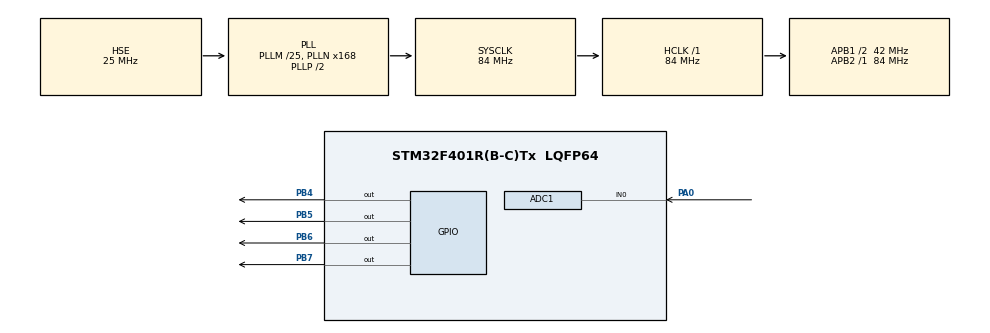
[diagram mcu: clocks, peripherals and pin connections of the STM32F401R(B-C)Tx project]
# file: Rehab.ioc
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ADC1.Channel-0\#ChannelRegularConversion=ADC_CHANNEL_0
ADC1.ContinuousConvMode=ENABLE
ADC1.DMAContinuousRequests=ENABLE
ADC1.NbrOfConversion=1
ADC1.NbrOfConversionFlag=1
ADC1.Rank-0\#ChannelRegularConversion=1
ADC1.SamplingTime-0\#ChannelRegularConversion=ADC_SAMPLETIME_84CYCLES
ADC1.master=1
Dma.ADC1.0.Direction=DMA_PERIPH_TO_MEMORY
Dma.ADC1.0.FIFOMode=DMA_FIFOMODE_DISABLE
Dma.ADC1.0.Instance=DMA2_Stream0
Dma.ADC1.0.MemDataAlignment=DMA_MDATAALIGN_WORD
Dma.ADC1.0.MemInc=DMA_MINC_ENABLE
Dma.ADC1.0.Mode=DMA_CIRCULAR
Dma.ADC1.0.PeriphDataAlignment=DMA_PDATAALIGN_WORD
Dma.ADC1.0.PeriphInc=DMA_PINC_DISABLE
Dma.ADC1.0.Priority=DMA_PRIORITY_LOW
Dma.Request0=ADC1
Mcu.Family=STM32F4
Mcu.Name=STM32F401R(B-C)Tx
Mcu.Package=LQFP64
NVIC.ADC_IRQn=true\:1\:0\:true\:false\:true\:true\:true\:true
NVIC.DMA2_Stream0_IRQn=true\:0\:0\:false\:false\:true\:false\:true\:true
NVIC.PriorityGroup=NVIC_PRIORITYGROUP_4
PA0-WKUP.Signal=ADCx_IN0
PB4.Signal=GPIO_Output
PB5.Signal=GPIO_Output
PB6.Signal=GPIO_Output
PB7.Signal=GPIO_Output
PH0\ -\ OSC_IN.Mode=HSE-External-Oscillator
PH0\ -\ OSC_IN.Signal=RCC_OSC_IN
PH1\ -\ OSC_OUT.Mode=HSE-External-Oscillator
PH1\ -\ OSC_OUT.Signal=RCC_OSC_OUT
ProjectManager.HeapSize=0x200
ProjectManager.StackSize=0x400
ProjectManager.TargetToolchain=STM32CubeIDE
RCC.48MHZClocksFreq_Value=42000000
RCC.AHBFreq_Value=84000000
RCC.APB1CLKDivider=RCC_HCLK_DIV2
RCC.APB1Freq_Value=42000000
RCC.APB1TimFreq_Value=84000000
RCC.APB2Freq_Value=84000000
RCC.APB2TimFreq_Value=84000000
RCC.CortexFreq_Value=84000000
RCC.HCLKFreq_Value=84000000
RCC.HSE_VALUE=25000000
RCC.HSI_VALUE=16000000
RCC.LSE_VALUE=32768
RCC.PLLM=25
RCC.PLLN=168
RCC.PLLSourceVirtual=RCC_PLLSOURCE_HSE
RCC.SYSCLKFreq_VALUE=84000000
RCC.SYSCLKSource=RCC_SYSCLKSOURCE_PLLCLK
RCC.VCOOutputFreq_Value=168000000
SH.ADCx_IN0.0=ADC1_IN0,IN0
TIM10.Period=10000
TIM10.Prescaler=8400-1
TIM11.Period=10000
TIM11.Prescaler=8400-1
TIM9.Period=10000
TIM9.Prescaler=8400-1
VP_TIM10_VS_ClockSourceINT.Mode=Enable_Timer
VP_TIM11_VS_ClockSourceINT.Mode=Enable_Timer
VP_TIM9_VS_ClockSourceINT.Mode=Internal
board=custom

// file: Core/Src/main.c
/* USER CODE BEGIN Header */
/**
  ******************************************************************************
  * @file           : main.c
  * @brief          : Main program body
  ******************************************************************************
  * @attention
  *
  * Copyright (c) 2024 STMicroelectronics.
  * All rights reserved.
  *
  * This software is licensed under terms that can be found in the LICENSE file
  * in the root directory of this software component.
  * If no LICENSE file comes with this software, it is provided AS-IS.
  *
  ******************************************************************************
  */
/* USER CODE END Header */
#include "main.h"

/* USER CODE BEGIN Includes */
#include <stdio.h>
#include <string.h>
#include "actuator_user_defined.h"
/* USER CODE END Includes */

ADC_HandleTypeDef hadc1;
DMA_HandleTypeDef hdma_adc1;

TIM_HandleTypeDef htim9;
TIM_HandleTypeDef htim10;
TIM_HandleTypeDef htim11;

/* USER CODE BEGIN PV */
uint32_t rawValue[3];
/* USER CODE END PV */

void SystemClock_Config(void);
static void MX_GPIO_Init(void);
static void MX_DMA_Init(void);
static void MX_ADC1_Init(void);
static void MX_TIM9_Init(void);
static void MX_TIM10_Init(void);
static void MX_TIM11_Init(void);

int main(void)
{

  /* MCU Configuration--------------------------------------------------------*/

  /* Reset of all peripherals, Initializes the Flash interface and the Systick. */
  HAL_Init();

  /* Configure the system clock */
  SystemClock_Config();

  /* Initialize all configured peripherals */
  MX_GPIO_Init();
  MX_DMA_Init();
  MX_ADC1_Init();
  MX_TIM9_Init();
  MX_TIM10_Init();
  MX_TIM11_Init();
  /* USER CODE BEGIN 2 */
  HAL_ADC_Start_DMA(&hadc1,rawValue, 4);
  ACTUATOR_DISTANCE_MODE_INIT(&htim9, &htim10, &htim11);
//  while(rawValue[0] <25);
  uint32_t first_value =rawValue[0];
  uint32_t progress = first_value;
  int counter =0;
  /* Infinite loop */
  while (1)
  {
    /* USER CODE BEGIN 3 */
	  if (counter <31){
		  counter++;
		  ACTUATOR_DISTANCE_MODE(ACTUATOR_ONE, 30, ACTUATOR_MOVE_IN);
		  ACTUATOR_DISTANCE_MODE(ACTUATOR_ONE, 30, ACTUATOR_MOVE_OUT);
	  }
	  else{
		  counter=0;
		  progress =rawValue[0];
//		  HAL_Delay(60000);
	  }
  }
  /* USER CODE END 3 */
}

void SystemClock_Config(void)
{
  RCC_OscInitTypeDef RCC_OscInitStruct = {0};
  RCC_ClkInitTypeDef RCC_ClkInitStruct = {0};

  /** Configure the main internal regulator output voltage
  */
  __HAL_RCC_PWR_CLK_ENABLE();
  __HAL_PWR_VOLTAGESCALING_CONFIG(PWR_REGULATOR_VOLTAGE_SCALE2);

  /** Initializes the RCC Oscillators according to the specified parameters
  * in the RCC_OscInitTypeDef structure.
  */
  RCC_OscInitStruct.OscillatorType = RCC_OSCILLATORTYPE_HSE;
  RCC_OscInitStruct.HSEState = RCC_HSE_ON;
  RCC_OscInitStruct.PLL.PLLState = RCC_PLL_ON;
  RCC_OscInitStruct.PLL.PLLSource = RCC_PLLSOURCE_HSE;
  RCC_OscInitStruct.PLL.PLLM = 25;
  RCC_OscInitStruct.PLL.PLLN = 168;
  RCC_OscInitStruct.PLL.PLLP = RCC_PLLP_DIV2;
  RCC_OscInitStruct.PLL.PLLQ = 4;
  if (HAL_RCC_OscConfig(&RCC_OscInitStruct) != HAL_OK)
  {
    Error_Handler();
  }

  /** Initializes the CPU, AHB and APB buses clocks
  */
  RCC_ClkInitStruct.ClockType = RCC_CLOCKTYPE_HCLK|RCC_CLOCKTYPE_SYSCLK
                              |RCC_CLOCKTYPE_PCLK1|RCC_CLOCKTYPE_PCLK2;
  RCC_ClkInitStruct.SYSCLKSource = RCC_SYSCLKSOURCE_PLLCLK;
  RCC_ClkInitStruct.AHBCLKDivider = RCC_SYSCLK_DIV1;
  RCC_ClkInitStruct.APB1CLKDivider = RCC_HCLK_DIV2;
  RCC_ClkInitStruct.APB2CLKDivider = RCC_HCLK_DIV1;

  if (HAL_RCC_ClockConfig(&RCC_ClkInitStruct, FLASH_LATENCY_2) != HAL_OK)
  {
    Error_Handler();
  }
}

static void MX_ADC1_Init(void)
{

  ADC_ChannelConfTypeDef sConfig = {0};

  /** Configure the global features of the ADC (Clock, Resolution, Data Alignment and number of conversion)
  */
  hadc1.Instance = ADC1;
  hadc1.Init.ClockPrescaler = ADC_CLOCK_SYNC_PCLK_DIV4;
  hadc1.Init.Resolution = ADC_RESOLUTION_12B;
  hadc1.Init.ScanConvMode = DISABLE;
  hadc1.Init.ContinuousConvMode = ENABLE;
  hadc1.Init.DiscontinuousConvMode = DISABLE;
  hadc1.Init.ExternalTrigConvEdge = ADC_EXTERNALTRIGCONVEDGE_NONE;
  hadc1.Init.ExternalTrigConv = ADC_SOFTWARE_START;
  hadc1.Init.DataAlign = ADC_DATAALIGN_RIGHT;
  hadc1.Init.NbrOfConversion = 1;
  hadc1.Init.DMAContinuousRequests = ENABLE;
  hadc1.Init.EOCSelection = ADC_EOC_SINGLE_CONV;
  if (HAL_ADC_Init(&hadc1) != HAL_OK)
  {
    Error_Handler();
  }

  /** Configure for the selected ADC regular channel its corresponding rank in the sequencer and its sample time.
  */
  sConfig.Channel = ADC_CHANNEL_0;
  sConfig.Rank = 1;
  sConfig.SamplingTime = ADC_SAMPLETIME_84CYCLES;
  if (HAL_ADC_ConfigChannel(&hadc1, &sConfig) != HAL_OK)
  {
    Error_Handler();
  }

}

static void MX_TIM9_Init(void)
{

  TIM_ClockConfigTypeDef sClockSourceConfig = {0};

  htim9.Instance = TIM9;
  htim9.Init.Prescaler = 8400-1;
  htim9.Init.CounterMode = TIM_COUNTERMODE_UP;
  htim9.Init.Period = 10000;
  htim9.Init.ClockDivision = TIM_CLOCKDIVISION_DIV1;
  htim9.Init.AutoReloadPreload = TIM_AUTORELOAD_PRELOAD_DISABLE;
  if (HAL_TIM_Base_Init(&htim9) != HAL_OK)
  {
    Error_Handler();
  }
  sClockSourceConfig.ClockSource = TIM_CLOCKSOURCE_INTERNAL;
  if (HAL_TIM_ConfigClockSource(&htim9, &sClockSourceConfig) != HAL_OK)
  {
    Error_Handler();
  }

}

static void MX_TIM10_Init(void)
{

  htim10.Instance = TIM10;
  htim10.Init.Prescaler = 8400-1;
  htim10.Init.CounterMode = TIM_COUNTERMODE_UP;
  htim10.Init.Period = 10000;
  htim10.Init.ClockDivision = TIM_CLOCKDIVISION_DIV1;
  htim10.Init.AutoReloadPreload = TIM_AUTORELOAD_PRELOAD_DISABLE;
  if (HAL_TIM_Base_Init(&htim10) != HAL_OK)
  {
    Error_Handler();
  }

}

static void MX_TIM11_Init(void)
{

  htim11.Instance = TIM11;
  htim11.Init.Prescaler = 8400-1;
  htim11.Init.CounterMode = TIM_COUNTERMODE_UP;
  htim11.Init.Period = 10000;
  htim11.Init.ClockDivision = TIM_CLOCKDIVISION_DIV1;
  htim11.Init.AutoReloadPreload = TIM_AUTORELOAD_PRELOAD_DISABLE;
  if (HAL_TIM_Base_Init(&htim11) != HAL_OK)
  {
    Error_Handler();
  }

}

static void MX_DMA_Init(void)
{

  /* DMA controller clock enable */
  __HAL_RCC_DMA2_CLK_ENABLE();

  /* DMA interrupt init */
  /* DMA2_Stream0_IRQn interrupt configuration */
  HAL_NVIC_SetPriority(DMA2_Stream0_IRQn, 0, 0);
  HAL_NVIC_EnableIRQ(DMA2_Stream0_IRQn);

}

static void MX_GPIO_Init(void)
{
  GPIO_InitTypeDef GPIO_InitStruct = {0};

  /* GPIO Ports Clock Enable */
  __HAL_RCC_GPIOH_CLK_ENABLE();
  __HAL_RCC_GPIOA_CLK_ENABLE();
  __HAL_RCC_GPIOB_CLK_ENABLE();

  /*Configure GPIO pin Output Level */
  HAL_GPIO_WritePin(GPIOB, GPIO_PIN_4|GPIO_PIN_5|GPIO_PIN_6|GPIO_PIN_7, GPIO_PIN_RESET);

  /*Configure GPIO pins : PB4 PB5 PB6 PB7 */
  GPIO_InitStruct.Pin = GPIO_PIN_4|GPIO_PIN_5|GPIO_PIN_6|GPIO_PIN_7;
  GPIO_InitStruct.Mode = GPIO_MODE_OUTPUT_PP;
  GPIO_InitStruct.Pull = GPIO_NOPULL;
  GPIO_InitStruct.Speed = GPIO_SPEED_FREQ_LOW;
  HAL_GPIO_Init(GPIOB, &GPIO_InitStruct);

}

void Error_Handler(void)
{
  __disable_irq();
  while (1)
  {
  }
}
